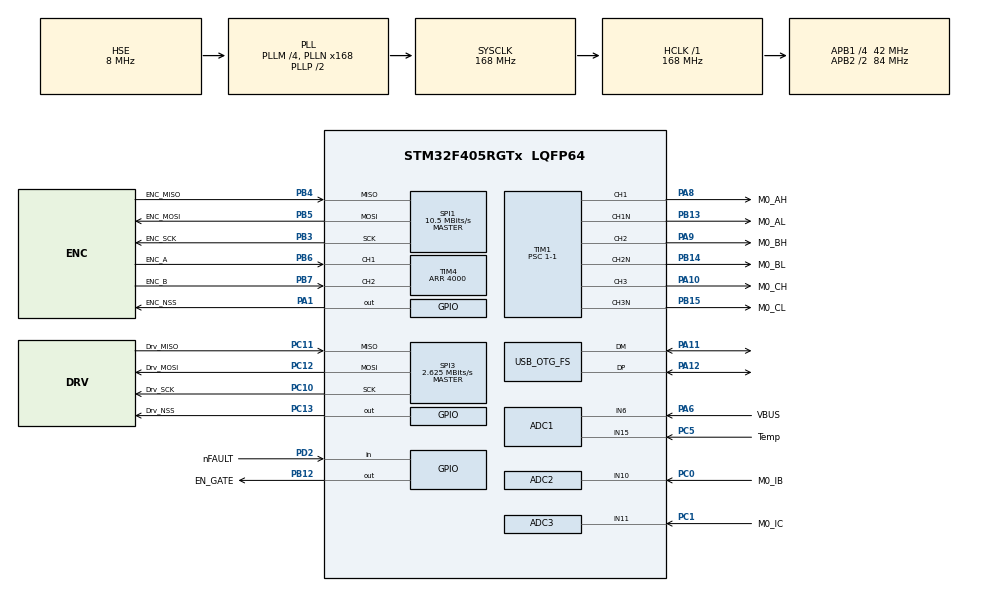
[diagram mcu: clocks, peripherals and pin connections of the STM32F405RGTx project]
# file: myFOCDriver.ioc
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ADC1.Channel-0\#ChannelRegularConversion=ADC_CHANNEL_15
ADC1.Channel-1\#ChannelInjectedConversion=ADC_CHANNEL_6
ADC1.ExternalTrigInjecConv=ADC_EXTERNALTRIGINJECCONV_T1_TRGO
ADC1.ExternalTrigInjecConvEdge=ADC_EXTERNALTRIGINJECCONVEDGE_RISINGFALLING
ADC1.InjNumberOfConversion=1
ADC1.InjectedOffset-1\#ChannelInjectedConversion=0
ADC1.InjectedRank-1\#ChannelInjectedConversion=1
ADC1.NbrOfConversion=1
ADC1.NbrOfConversionFlag=1
ADC1.Rank-0\#ChannelRegularConversion=1
ADC1.SamplingTime-0\#ChannelRegularConversion=ADC_SAMPLETIME_3CYCLES
ADC1.SamplingTime-1\#ChannelInjectedConversion=ADC_SAMPLETIME_3CYCLES
ADC1.master=1
ADC2.Channel-3\#ChannelRegularConversion=ADC_CHANNEL_10
ADC2.Channel-4\#ChannelInjectedConversion=ADC_CHANNEL_10
ADC2.ExternalTrigInjecConv=ADC_EXTERNALTRIGINJECCONV_T1_CC4
ADC2.ExternalTrigInjecConvEdge=ADC_EXTERNALTRIGINJECCONVEDGE_RISING
ADC2.InjNumberOfConversion=1
ADC2.InjectedOffset-4\#ChannelInjectedConversion=0
ADC2.InjectedRank-4\#ChannelInjectedConversion=1
ADC2.NbrOfConversion=1
ADC2.NbrOfConversionFlag=1
ADC2.Rank-3\#ChannelRegularConversion=1
ADC2.SamplingTime-3\#ChannelRegularConversion=ADC_SAMPLETIME_3CYCLES
ADC2.SamplingTime-4\#ChannelInjectedConversion=ADC_SAMPLETIME_3CYCLES
ADC3.Channel-4\#ChannelRegularConversion=ADC_CHANNEL_11
ADC3.Channel-5\#ChannelInjectedConversion=ADC_CHANNEL_11
ADC3.ExternalTrigInjecConv=ADC_EXTERNALTRIGINJECCONV_T1_CC4
ADC3.ExternalTrigInjecConvEdge=ADC_EXTERNALTRIGINJECCONVEDGE_RISING
ADC3.InjNumberOfConversion=1
ADC3.InjectedOffset-5\#ChannelInjectedConversion=0
ADC3.InjectedRank-5\#ChannelInjectedConversion=1
ADC3.NbrOfConversionFlag=1
ADC3.Rank-4\#ChannelRegularConversion=1
ADC3.SamplingTime-4\#ChannelRegularConversion=ADC_SAMPLETIME_3CYCLES
ADC3.SamplingTime-5\#ChannelInjectedConversion=ADC_SAMPLETIME_3CYCLES
Dma.ADC1.2.Direction=DMA_PERIPH_TO_MEMORY
Dma.ADC1.2.FIFOMode=DMA_FIFOMODE_DISABLE
Dma.ADC1.2.Instance=DMA2_Stream0
Dma.ADC1.2.MemDataAlignment=DMA_MDATAALIGN_HALFWORD
Dma.ADC1.2.MemInc=DMA_MINC_ENABLE
Dma.ADC1.2.Mode=DMA_CIRCULAR
Dma.ADC1.2.PeriphDataAlignment=DMA_PDATAALIGN_HALFWORD
Dma.ADC1.2.PeriphInc=DMA_PINC_DISABLE
Dma.ADC1.2.Priority=DMA_PRIORITY_LOW
Dma.Request0=SPI3_RX
Dma.Request1=SPI3_TX
Dma.Request2=ADC1
Dma.Request3=SPI1_RX
Dma.Request4=SPI1_TX
Dma.SPI1_RX.3.Direction=DMA_PERIPH_TO_MEMORY
Dma.SPI1_RX.3.FIFOMode=DMA_FIFOMODE_DISABLE
Dma.SPI1_RX.3.Instance=DMA2_Stream2
Dma.SPI1_RX.3.MemDataAlignment=DMA_MDATAALIGN_HALFWORD
Dma.SPI1_RX.3.MemInc=DMA_MINC_ENABLE
Dma.SPI1_RX.3.Mode=DMA_NORMAL
Dma.SPI1_RX.3.PeriphDataAlignment=DMA_PDATAALIGN_HALFWORD
Dma.SPI1_RX.3.PeriphInc=DMA_PINC_DISABLE
Dma.SPI1_RX.3.Priority=DMA_PRIORITY_LOW
Dma.SPI1_TX.4.Direction=DMA_MEMORY_TO_PERIPH
Dma.SPI1_TX.4.FIFOMode=DMA_FIFOMODE_DISABLE
Dma.SPI1_TX.4.Instance=DMA2_Stream3
Dma.SPI1_TX.4.MemDataAlignment=DMA_MDATAALIGN_HALFWORD
Dma.SPI1_TX.4.MemInc=DMA_MINC_ENABLE
Dma.SPI1_TX.4.Mode=DMA_CIRCULAR
Dma.SPI1_TX.4.PeriphDataAlignment=DMA_PDATAALIGN_HALFWORD
Dma.SPI1_TX.4.PeriphInc=DMA_PINC_DISABLE
Dma.SPI1_TX.4.Priority=DMA_PRIORITY_LOW
Dma.SPI3_RX.0.Direction=DMA_PERIPH_TO_MEMORY
Dma.SPI3_RX.0.FIFOMode=DMA_FIFOMODE_DISABLE
Dma.SPI3_RX.0.Instance=DMA1_Stream0
Dma.SPI3_RX.0.MemDataAlignment=DMA_MDATAALIGN_HALFWORD
Dma.SPI3_RX.0.MemInc=DMA_MINC_ENABLE
Dma.SPI3_RX.0.Mode=DMA_NORMAL
Dma.SPI3_RX.0.PeriphDataAlignment=DMA_PDATAALIGN_HALFWORD
Dma.SPI3_RX.0.PeriphInc=DMA_PINC_DISABLE
Dma.SPI3_RX.0.Priority=DMA_PRIORITY_LOW
Dma.SPI3_TX.1.Direction=DMA_MEMORY_TO_PERIPH
Dma.SPI3_TX.1.FIFOMode=DMA_FIFOMODE_DISABLE
Dma.SPI3_TX.1.Instance=DMA1_Stream5
Dma.SPI3_TX.1.MemDataAlignment=DMA_MDATAALIGN_HALFWORD
Dma.SPI3_TX.1.MemInc=DMA_MINC_ENABLE
Dma.SPI3_TX.1.Mode=DMA_NORMAL
Dma.SPI3_TX.1.PeriphDataAlignment=DMA_PDATAALIGN_HALFWORD
Dma.SPI3_TX.1.PeriphInc=DMA_PINC_DISABLE
Dma.SPI3_TX.1.Priority=DMA_PRIORITY_LOW
Mcu.Family=STM32F4
Mcu.Name=STM32F405RGTx
Mcu.Package=LQFP64
NVIC.DMA1_Stream0_IRQn=true\:0\:0\:false\:false\:true\:false\:true\:true
NVIC.DMA1_Stream5_IRQn=true\:0\:0\:false\:false\:true\:false\:true\:true
NVIC.DMA2_Stream0_IRQn=true\:0\:0\:false\:false\:true\:false\:true\:true
NVIC.DMA2_Stream2_IRQn=true\:0\:0\:false\:false\:true\:false\:true\:true
NVIC.DMA2_Stream3_IRQn=true\:0\:0\:false\:false\:true\:false\:true\:true
NVIC.OTG_FS_IRQn=true\:0\:0\:false\:false\:true\:false\:true\:true
NVIC.PriorityGroup=NVIC_PRIORITYGROUP_4
NVIC.SPI3_IRQn=true\:0\:0\:false\:false\:true\:true\:true\:true
NVIC.TIM1_UP_TIM10_IRQn=true\:0\:0\:false\:false\:true\:true\:true\:true
NVIC.TIM8_TRG_COM_TIM14_IRQn=true\:0\:0\:false\:false\:true\:true\:true\:true
PA1.GPIO_Label=ENC_NSS
PA1.Signal=GPIO_Output
PA10.GPIO_Label=M0_CH
PA10.GPIO_Speed=GPIO_SPEED_FREQ_HIGH
PA10.Signal=S_TIM1_CH3
PA11.Mode=Device_Only
PA11.Signal=USB_OTG_FS_DM
PA12.Mode=Device_Only
PA12.Signal=USB_OTG_FS_DP
PA6.GPIO_Label=VBUS
PA6.Signal=ADCx_IN6
PA8.GPIO_Label=M0_AH
PA8.GPIO_Speed=GPIO_SPEED_FREQ_HIGH
PA8.Signal=S_TIM1_CH1
PA9.GPIO_Label=M0_BH
PA9.GPIO_Speed=GPIO_SPEED_FREQ_HIGH
PA9.Signal=S_TIM1_CH2
PB12.GPIO_Label=EN_GATE
PB12.GPIO_PuPd=GPIO_NOPULL
PB12.PinState=GPIO_PIN_SET
PB12.Signal=GPIO_Output
PB13.GPIO_Label=M0_AL
PB13.GPIO_Speed=GPIO_SPEED_FREQ_HIGH
PB13.Mode=PWM Generation1 CH1 CH1N
PB13.Signal=TIM1_CH1N
PB14.GPIO_Label=M0_BL
PB14.GPIO_Speed=GPIO_SPEED_FREQ_HIGH
PB14.Mode=PWM Generation2 CH2 CH2N
PB14.Signal=TIM1_CH2N
PB15.GPIO_Label=M0_CL
PB15.GPIO_Speed=GPIO_SPEED_FREQ_HIGH
PB15.Mode=PWM Generation3 CH3 CH3N
PB15.Signal=TIM1_CH3N
PB3.GPIO_Label=ENC_SCK
PB3.Mode=Full_Duplex_Master
PB3.Signal=SPI1_SCK
PB4.GPIO_Label=ENC_MISO
PB4.Mode=Full_Duplex_Master
PB4.Signal=SPI1_MISO
PB5.GPIO_Label=ENC_MOSI
PB5.Mode=Full_Duplex_Master
PB5.Signal=SPI1_MOSI
PB6.GPIO_Label=ENC_A
PB6.Signal=S_TIM4_CH1
PB7.GPIO_Label=ENC_B
PB7.Signal=S_TIM4_CH2
PC0.GPIO_Label=M0_IB
PC0.Signal=ADCx_IN10
PC1.GPIO_Label=M0_IC
PC1.Signal=ADCx_IN11
PC10.GPIO_Label=Drv_SCK
PC10.Mode=Full_Duplex_Master
PC10.Signal=SPI3_SCK
PC11.GPIO_Label=Drv_MISO
PC11.Mode=Full_Duplex_Master
PC11.Signal=SPI3_MISO
PC12.GPIO_Label=Drv_MOSI
PC12.Mode=Full_Duplex_Master
PC12.Signal=SPI3_MOSI
PC13-ANTI_TAMP.GPIO_Label=Drv_NSS
PC13-ANTI_TAMP.GPIO_PuPd=GPIO_NOPULL
PC13-ANTI_TAMP.PinState=GPIO_PIN_SET
PC13-ANTI_TAMP.Signal=GPIO_Output
PC5.GPIO_Label=Temp
PC5.Signal=ADCx_IN15
PD2.GPIO_Label=nFAULT
PD2.GPIO_PuPd=GPIO_PULLUP
PD2.Signal=GPIO_Input
PH0-OSC_IN.Mode=HSE-External-Oscillator
PH0-OSC_IN.Signal=RCC_OSC_IN
PH1-OSC_OUT.Mode=HSE-External-Oscillator
PH1-OSC_OUT.Signal=RCC_OSC_OUT
ProjectManager.HeapSize=0x3C00
ProjectManager.StackSize=0x800
ProjectManager.TargetToolchain=STM32CubeIDE
RCC.48MHZClocksFreq_Value=48000000
RCC.AHBFreq_Value=168000000
RCC.APB1CLKDivider=RCC_HCLK_DIV4
RCC.APB1Freq_Value=42000000
RCC.APB1TimFreq_Value=84000000
RCC.APB2CLKDivider=RCC_HCLK_DIV2
RCC.APB2Freq_Value=84000000
RCC.APB2TimFreq_Value=168000000
RCC.CortexFreq_Value=168000000
RCC.HCLKFreq_Value=168000000
RCC.HSE_VALUE=8000000
RCC.HSI_VALUE=16000000
RCC.LSE_VALUE=32768
RCC.PLLM=4
RCC.PLLN=168
RCC.PLLQ=7
RCC.SYSCLKFreq_VALUE=168000000
RCC.SYSCLKSource=RCC_SYSCLKSOURCE_PLLCLK
RCC.VCOOutputFreq_Value=336000000
SH.ADCx_IN10.0=ADC2_IN10,IN10
SH.ADCx_IN11.0=ADC3_IN11,IN11
SH.ADCx_IN15.0=ADC1_IN15,IN15
SH.ADCx_IN6.0=ADC1_IN6,IN6
SH.S_TIM1_CH1.0=TIM1_CH1,PWM Generation1 CH1 CH1N
SH.S_TIM1_CH2.0=TIM1_CH2,PWM Generation2 CH2 CH2N
SH.S_TIM1_CH3.0=TIM1_CH3,PWM Generation3 CH3 CH3N
SH.S_TIM4_CH1.0=TIM4_CH1,Encoder_Interface
SH.S_TIM4_CH2.0=TIM4_CH2,Encoder_Interface
SPI1.BaudRatePrescaler=SPI_BAUDRATEPRESCALER_8
SPI1.CLKPhase=SPI_PHASE_2EDGE
SPI1.CalculateBaudRate=10.5 MBits/s
SPI1.DataSize=SPI_DATASIZE_16BIT
SPI1.Direction=SPI_DIRECTION_2LINES
SPI1.Mode=SPI_MODE_MASTER
SPI1.VirtualType=VM_MASTER
SPI3.BaudRatePrescaler=SPI_BAUDRATEPRESCALER_16
SPI3.CLKPhase=SPI_PHASE_2EDGE
SPI3.CalculateBaudRate=2.625 MBits/s
SPI3.DataSize=SPI_DATASIZE_16BIT
SPI3.Direction=SPI_DIRECTION_2LINES
SPI3.Mode=SPI_MODE_MASTER
SPI3.VirtualType=VM_MASTER
STMicroelectronics.X-CUBE-ALGOBUILD.1.3.0.LibraryCcDSPOoLibraryJjDSPOoLibrary=true
TIM1.Channel-PWM\ Generation1\ CH1\ CH1N=TIM_CHANNEL_1
TIM1.Channel-PWM\ Generation2\ CH2\ CH2N=TIM_CHANNEL_2
TIM1.Channel-PWM\ Generation3\ CH3\ CH3N=TIM_CHANNEL_3
TIM1.Channel-PWM\ Generation4\ No\ Output=TIM_CHANNEL_4
TIM1.ClockDivision=TIM_CLOCKDIVISION_DIV1
TIM1.CounterMode=TIM_COUNTERMODE_CENTERALIGNED1
TIM1.DeadTime=20
TIM1.OCMode_PWM-PWM\ Generation1\ CH1\ CH1N=TIM_OCMODE_PWM2
TIM1.OCMode_PWM-PWM\ Generation2\ CH2\ CH2N=TIM_OCMODE_PWM2
TIM1.OCMode_PWM-PWM\ Generation3\ CH3\ CH3N=TIM_OCMODE_PWM2
TIM1.OffStateIDLEMode=TIM_OSSI_ENABLE
TIM1.OffStateRunMode=TIM_OSSR_ENABLE
TIM1.Period=168000000/20000/2
TIM1.Prescaler=1-1
TIM1.Pulse-PWM\ Generation4\ No\ Output=1
TIM1.RepetitionCounter=1
TIM1.TIM_MasterOutputTrigger=TIM_TRGO_OC4REF
TIM1.TIM_MasterSlaveMode=TIM_MASTERSLAVEMODE_DISABLE
TIM14.AutoReloadPreload=TIM_AUTORELOAD_PRELOAD_ENABLE
TIM14.Period=1000-1
TIM14.Prescaler=42-1
TIM4.AutoReloadPreload=TIM_AUTORELOAD_PRELOAD_ENABLE
TIM4.EncoderMode=TIM_ENCODERMODE_TI12
TIM4.IC1Filter=4
TIM4.IC2Filter=4
TIM4.Period=4000
USB_DEVICE.APP_RX_DATA_SIZE-CDC_FS=64
USB_DEVICE.APP_TX_DATA_SIZE-CDC_FS=64
USB_DEVICE.CLASS_NAME_FS=CDC
USB_DEVICE.VirtualMode-CDC_FS=Cdc
USB_DEVICE.VirtualModeFS=Cdc_FS
USB_OTG_FS.VirtualMode=Device_Only
VP_STMicroelectronics.X-CUBE-ALGOBUILD_VS_DSPOoLibraryJjLibrary_1.3.0_1.3.0.Mode=DSPOoLibraryJjLibrary
VP_TIM14_VS_ClockSourceINT.Mode=Enable_Timer
VP_TIM1_VS_ClockSourceINT.Mode=Internal
VP_TIM1_VS_no_output4.Mode=PWM Generation4 No Output
VP_USB_DEVICE_VS_USB_DEVICE_CDC_FS.Mode=CDC_FS
board=custom

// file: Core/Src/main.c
/* USER CODE BEGIN Header */
/**
  ******************************************************************************
  * @file           : main.c
  * @brief          : Main program body
  ******************************************************************************
  * @attention
  *
  * Copyright (c) 2023 STMicroelectronics.
  * All rights reserved.
  *
  * This software is licensed under terms that can be found in the LICENSE file
  * in the root directory of this software component.
  * If no LICENSE file comes with this software, it is provided AS-IS.
  *
  ******************************************************************************
  */
/* USER CODE END Header */
#include "main.h"
#include "adc.h"
#include "dma.h"
#include "spi.h"
#include "tim.h"
#include "usb_device.h"
#include "gpio.h"

void SystemClock_Config(void);

int main(void)
{

  /* MCU Configuration--------------------------------------------------------*/

  /* Reset of all peripherals, Initializes the Flash interface and the Systick. */
  HAL_Init();

  /* Configure the system clock */
  SystemClock_Config();

  /* Initialize all configured peripherals */
  MX_GPIO_Init();
  MX_DMA_Init();
  MX_USB_DEVICE_Init();
  MX_SPI3_Init();
  MX_TIM1_Init();
  MX_TIM14_Init();
  MX_ADC1_Init();
  MX_ADC2_Init();
  MX_SPI1_Init();
  MX_TIM4_Init();
  MX_ADC3_Init();
  /* USER CODE BEGIN 2 */

  App_Main();
  /* USER CODE END 2 */

  /* Infinite loop */
  while (1)
  {

  }
}

void SystemClock_Config(void)
{
  RCC_OscInitTypeDef RCC_OscInitStruct = {0};
  RCC_ClkInitTypeDef RCC_ClkInitStruct = {0};

  /** Configure the main internal regulator output voltage
  */
  __HAL_RCC_PWR_CLK_ENABLE();
  __HAL_PWR_VOLTAGESCALING_CONFIG(PWR_REGULATOR_VOLTAGE_SCALE1);

  /** Initializes the RCC Oscillators according to the specified parameters
  * in the RCC_OscInitTypeDef structure.
  */
  RCC_OscInitStruct.OscillatorType = RCC_OSCILLATORTYPE_HSE;
  RCC_OscInitStruct.HSEState = RCC_HSE_ON;
  RCC_OscInitStruct.PLL.PLLState = RCC_PLL_ON;
  RCC_OscInitStruct.PLL.PLLSource = RCC_PLLSOURCE_HSE;
  RCC_OscInitStruct.PLL.PLLM = 4;
  RCC_OscInitStruct.PLL.PLLN = 168;
  RCC_OscInitStruct.PLL.PLLP = RCC_PLLP_DIV2;
  RCC_OscInitStruct.PLL.PLLQ = 7;
  if (HAL_RCC_OscConfig(&RCC_OscInitStruct) != HAL_OK)
  {
    Error_Handler();
  }

  /** Initializes the CPU, AHB and APB buses clocks
  */
  RCC_ClkInitStruct.ClockType = RCC_CLOCKTYPE_HCLK|RCC_CLOCKTYPE_SYSCLK
                              |RCC_CLOCKTYPE_PCLK1|RCC_CLOCKTYPE_PCLK2;
  RCC_ClkInitStruct.SYSCLKSource = RCC_SYSCLKSOURCE_PLLCLK;
  RCC_ClkInitStruct.AHBCLKDivider = RCC_SYSCLK_DIV1;
  RCC_ClkInitStruct.APB1CLKDivider = RCC_HCLK_DIV4;
  RCC_ClkInitStruct.APB2CLKDivider = RCC_HCLK_DIV2;

  if (HAL_RCC_ClockConfig(&RCC_ClkInitStruct, FLASH_LATENCY_5) != HAL_OK)
  {
    Error_Handler();
  }
}

void Error_Handler(void)
{
  __disable_irq();
  while (1)
  {
  }
}
